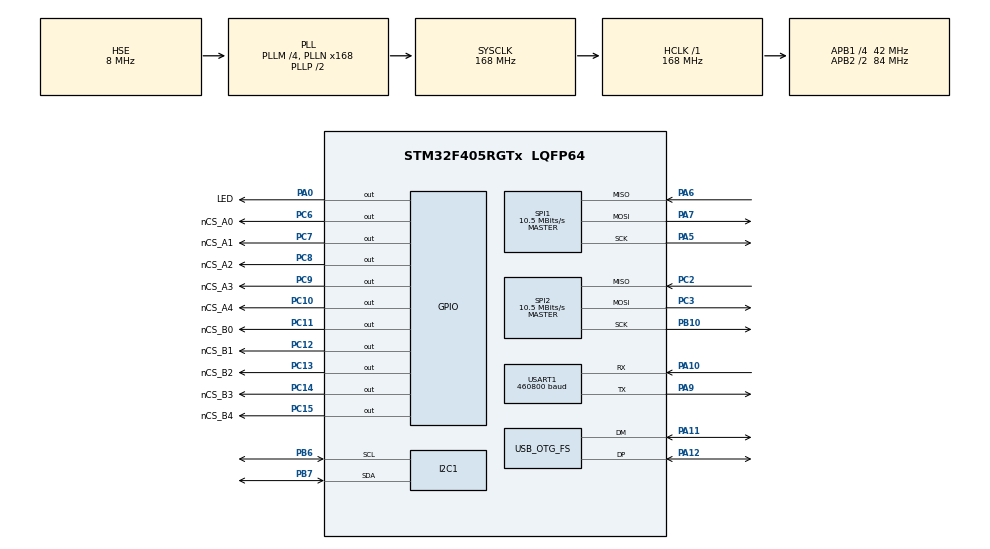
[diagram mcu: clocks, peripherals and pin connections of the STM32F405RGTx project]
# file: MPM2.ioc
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Dma.Request0=USART1_RX
Dma.USART1_RX.0.Direction=DMA_PERIPH_TO_MEMORY
Dma.USART1_RX.0.FIFOMode=DMA_FIFOMODE_DISABLE
Dma.USART1_RX.0.Instance=DMA2_Stream2
Dma.USART1_RX.0.MemDataAlignment=DMA_MDATAALIGN_BYTE
Dma.USART1_RX.0.MemInc=DMA_MINC_ENABLE
Dma.USART1_RX.0.Mode=DMA_NORMAL
Dma.USART1_RX.0.PeriphDataAlignment=DMA_PDATAALIGN_BYTE
Dma.USART1_RX.0.PeriphInc=DMA_PINC_DISABLE
Dma.USART1_RX.0.Priority=DMA_PRIORITY_LOW
FREERTOS.Tasks01=defaultTask,24,256,StartDefaultTask,Default,NULL,Dynamic,NULL,NULL;IdleTask,8,256,IdleTaskEntry,Default,NULL,Dynamic,NULL,NULL;MeasTask,8,256,MeasTaskEntry,Default,NULL,Dynamic,NULL,NULL;DisplayTask,8,256,DisplayTaskEntry,Default,NULL,Dynamic,NULL,NULL;SysTask,8,256,SysTaskEntry,Default,NULL,Dynamic,NULL,NULL
FREERTOS.configMINIMAL_STACK_SIZE=256
FREERTOS.configUSE_NEWLIB_REENTRANT=1
Mcu.Family=STM32F4
Mcu.Name=STM32F405RGTx
Mcu.Package=LQFP64
NVIC.DMA2_Stream2_IRQn=true\:5\:0\:false\:false\:true\:true\:false\:true\:true
NVIC.OTG_FS_IRQn=true\:5\:0\:false\:false\:true\:true\:false\:true\:true
NVIC.PriorityGroup=NVIC_PRIORITYGROUP_4
NVIC.TIM2_IRQn=true\:15\:0\:false\:false\:true\:false\:false\:true\:true
NVIC.TimeBase=TIM2_IRQn
NVIC.TimeBaseIP=TIM2
PA0-WKUP.GPIO_Label=LED
PA0-WKUP.GPIO_ModeDefaultOutputPP=GPIO_MODE_OUTPUT_OD
PA0-WKUP.GPIO_PuPd=GPIO_NOPULL
PA0-WKUP.PinState=GPIO_PIN_SET
PA0-WKUP.Signal=GPIO_Output
PA10.Mode=Asynchronous
PA10.Signal=USART1_RX
PA11.Mode=Device_Only
PA11.Signal=USB_OTG_FS_DM
PA12.Mode=Device_Only
PA12.Signal=USB_OTG_FS_DP
PA13.Signal=SYS_JTMS-SWDIO
PA14.Signal=SYS_JTCK-SWCLK
PA5.Mode=Full_Duplex_Master
PA5.Signal=SPI1_SCK
PA6.Mode=Full_Duplex_Master
PA6.Signal=SPI1_MISO
PA7.Mode=Full_Duplex_Master
PA7.Signal=SPI1_MOSI
PA9.Mode=Asynchronous
PA9.Signal=USART1_TX
PB10.Mode=Full_Duplex_Master
PB10.Signal=SPI2_SCK
PB6.Mode=I2C
PB6.Signal=I2C1_SCL
PB7.Mode=I2C
PB7.Signal=I2C1_SDA
PC10.GPIO_Label=nCS_A4
PC10.GPIO_PuPd=GPIO_PULLUP
PC10.GPIO_Speed=GPIO_SPEED_FREQ_HIGH
PC10.PinState=GPIO_PIN_SET
PC10.Signal=GPIO_Output
PC11.GPIO_Label=nCS_B0
PC11.GPIO_PuPd=GPIO_PULLUP
PC11.GPIO_Speed=GPIO_SPEED_FREQ_HIGH
PC11.PinState=GPIO_PIN_SET
PC11.Signal=GPIO_Output
PC12.GPIO_Label=nCS_B1
PC12.GPIO_PuPd=GPIO_PULLUP
PC12.GPIO_Speed=GPIO_SPEED_FREQ_HIGH
PC12.PinState=GPIO_PIN_SET
PC12.Signal=GPIO_Output
PC13-ANTI_TAMP.GPIO_Label=nCS_B2
PC13-ANTI_TAMP.GPIO_PuPd=GPIO_PULLUP
PC13-ANTI_TAMP.PinState=GPIO_PIN_SET
PC13-ANTI_TAMP.Signal=GPIO_Output
PC14-OSC32_IN.GPIO_Label=nCS_B3
PC14-OSC32_IN.GPIO_PuPd=GPIO_PULLUP
PC14-OSC32_IN.PinState=GPIO_PIN_SET
PC14-OSC32_IN.Signal=GPIO_Output
PC15-OSC32_OUT.GPIO_Label=nCS_B4
PC15-OSC32_OUT.GPIO_PuPd=GPIO_PULLUP
PC15-OSC32_OUT.PinState=GPIO_PIN_SET
PC15-OSC32_OUT.Signal=GPIO_Output
PC2.Mode=Full_Duplex_Master
PC2.Signal=SPI2_MISO
PC3.Mode=Full_Duplex_Master
PC3.Signal=SPI2_MOSI
PC6.GPIO_Label=nCS_A0
PC6.GPIO_PuPd=GPIO_PULLUP
PC6.GPIO_Speed=GPIO_SPEED_FREQ_HIGH
PC6.PinState=GPIO_PIN_SET
PC6.Signal=GPIO_Output
PC7.GPIO_Label=nCS_A1
PC7.GPIO_PuPd=GPIO_PULLUP
PC7.GPIO_Speed=GPIO_SPEED_FREQ_HIGH
PC7.PinState=GPIO_PIN_SET
PC7.Signal=GPIO_Output
PC8.GPIO_Label=nCS_A2
PC8.GPIO_PuPd=GPIO_PULLUP
PC8.GPIO_Speed=GPIO_SPEED_FREQ_HIGH
PC8.PinState=GPIO_PIN_SET
PC8.Signal=GPIO_Output
PC9.GPIO_Label=nCS_A3
PC9.GPIO_PuPd=GPIO_PULLUP
PC9.GPIO_Speed=GPIO_SPEED_FREQ_HIGH
PC9.PinState=GPIO_PIN_SET
PC9.Signal=GPIO_Output
PH0-OSC_IN.Mode=HSE-External-Oscillator
PH0-OSC_IN.Signal=RCC_OSC_IN
PH1-OSC_OUT.Mode=HSE-External-Oscillator
PH1-OSC_OUT.Signal=RCC_OSC_OUT
ProjectManager.HeapSize=0x200
ProjectManager.StackSize=0x400
ProjectManager.TargetToolchain=STM32CubeIDE
RCC.48MHZClocksFreq_Value=48000000
RCC.AHBFreq_Value=168000000
RCC.APB1CLKDivider=RCC_HCLK_DIV4
RCC.APB1Freq_Value=42000000
RCC.APB1TimFreq_Value=84000000
RCC.APB2CLKDivider=RCC_HCLK_DIV2
RCC.APB2Freq_Value=84000000
RCC.APB2TimFreq_Value=168000000
RCC.CortexFreq_Value=168000000
RCC.HCLKFreq_Value=168000000
RCC.HSE_VALUE=8000000
RCC.HSI_VALUE=16000000
RCC.LSE_VALUE=32768
RCC.PLLM=4
RCC.PLLN=168
RCC.PLLQ=7
RCC.PWR_Regulator_Voltage_Scale=PWR_REGULATOR_VOLTAGE_SCALE1
RCC.SYSCLKFreq_VALUE=168000000
RCC.SYSCLKSource=RCC_SYSCLKSOURCE_PLLCLK
RCC.VCOOutputFreq_Value=336000000
SPI1.BaudRatePrescaler=SPI_BAUDRATEPRESCALER_8
SPI1.CLKPhase=SPI_PHASE_1EDGE
SPI1.CLKPolarity=SPI_POLARITY_HIGH
SPI1.CalculateBaudRate=10.5 MBits/s
SPI1.DataSize=SPI_DATASIZE_8BIT
SPI1.Direction=SPI_DIRECTION_2LINES
SPI1.Mode=SPI_MODE_MASTER
SPI1.VirtualType=VM_MASTER
SPI2.BaudRatePrescaler=SPI_BAUDRATEPRESCALER_4
SPI2.CLKPolarity=SPI_POLARITY_HIGH
SPI2.CalculateBaudRate=10.5 MBits/s
SPI2.Direction=SPI_DIRECTION_2LINES
SPI2.Mode=SPI_MODE_MASTER
SPI2.VirtualType=VM_MASTER
USART1.BaudRate=460800
USART1.VirtualMode=VM_ASYNC
USB_DEVICE.CLASS_NAME_FS=CDC
USB_DEVICE.MANUFACTURER_STRING-CDC_FS=ioko.eu
USB_DEVICE.PRODUCT_STRING_CDC_FS=MPM Virtual ComPort
USB_DEVICE.VirtualMode-CDC_FS=Cdc
USB_DEVICE.VirtualModeFS=Cdc_FS
USB_OTG_FS.VirtualMode=Device_Only
VP_FREERTOS_VS_CMSIS_V2.Mode=CMSIS_V2
VP_SYS_VS_tim2.Mode=TIM2
VP_USB_DEVICE_VS_USB_DEVICE_CDC_FS.Mode=CDC_FS
board=custom

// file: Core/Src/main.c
/* USER CODE BEGIN Header */
/**
  ******************************************************************************
  * @file           : main.c
  * @brief          : Main program body
  ******************************************************************************
  * @attention
  *
  * Copyright (c) 2024 STMicroelectronics.
  * All rights reserved.
  *
  * This software is licensed under terms that can be found in the LICENSE file
  * in the root directory of this software component.
  * If no LICENSE file comes with this software, it is provided AS-IS.
  *
  ******************************************************************************
  */
/* USER CODE END Header */
#include "main.h"
#include "cmsis_os.h"
#include "usb_device.h"

I2C_HandleTypeDef hi2c1;

SPI_HandleTypeDef hspi1;
SPI_HandleTypeDef hspi2;

UART_HandleTypeDef huart1;
DMA_HandleTypeDef hdma_usart1_rx;

/* Definitions for defaultTask */
osThreadId_t defaultTaskHandle;
const osThreadAttr_t defaultTask_attributes = {
  .name = "defaultTask",
  .stack_size = 256 * 4,
  .priority = (osPriority_t) osPriorityNormal,
};
/* Definitions for IdleTask */
osThreadId_t IdleTaskHandle;
const osThreadAttr_t IdleTask_attributes = {
  .name = "IdleTask",
  .stack_size = 256 * 4,
  .priority = (osPriority_t) osPriorityLow,
};
/* Definitions for MeasTask */
osThreadId_t MeasTaskHandle;
const osThreadAttr_t MeasTask_attributes = {
  .name = "MeasTask",
  .stack_size = 256 * 4,
  .priority = (osPriority_t) osPriorityLow,
};
/* Definitions for DisplayTask */
osThreadId_t DisplayTaskHandle;
const osThreadAttr_t DisplayTask_attributes = {
  .name = "DisplayTask",
  .stack_size = 256 * 4,
  .priority = (osPriority_t) osPriorityLow,
};
/* Definitions for SysTask */
osThreadId_t SysTaskHandle;
const osThreadAttr_t SysTask_attributes = {
  .name = "SysTask",
  .stack_size = 256 * 4,
  .priority = (osPriority_t) osPriorityLow,
};

void SystemClock_Config(void);
static void MX_GPIO_Init(void);
static void MX_DMA_Init(void);
static void MX_SPI1_Init(void);
static void MX_SPI2_Init(void);
static void MX_USART1_UART_Init(void);
static void MX_I2C1_Init(void);
void StartDefaultTask(void *argument);
void IdleTaskEntry(void *argument);
void MeasTaskEntry(void *argument);
void DisplayTaskEntry(void *argument);
void SysTaskEntry(void *argument);

int main(void)
{

  /* MCU Configuration--------------------------------------------------------*/

  /* Reset of all peripherals, Initializes the Flash interface and the Systick. */
  HAL_Init();

  /* Configure the system clock */
  SystemClock_Config();

  /* Initialize all configured peripherals */
  MX_GPIO_Init();
  MX_DMA_Init();
  MX_SPI1_Init();
  MX_SPI2_Init();
  MX_USART1_UART_Init();
  MX_I2C1_Init();

  /* Init scheduler */
  osKernelInitialize();

  /* Create the thread(s) */
  /* creation of defaultTask */
  defaultTaskHandle = osThreadNew(StartDefaultTask, NULL, &defaultTask_attributes);

  /* creation of IdleTask */
  IdleTaskHandle = osThreadNew(IdleTaskEntry, NULL, &IdleTask_attributes);

  /* creation of MeasTask */
  MeasTaskHandle = osThreadNew(MeasTaskEntry, NULL, &MeasTask_attributes);

  /* creation of DisplayTask */
  DisplayTaskHandle = osThreadNew(DisplayTaskEntry, NULL, &DisplayTask_attributes);

  /* creation of SysTask */
  SysTaskHandle = osThreadNew(SysTaskEntry, NULL, &SysTask_attributes);

  /* Start scheduler */
  osKernelStart();

  /* We should never get here as control is now taken by the scheduler */

  /* Infinite loop */
  while (1)
  {

  }
}

void SystemClock_Config(void)
{
  RCC_OscInitTypeDef RCC_OscInitStruct = {0};
  RCC_ClkInitTypeDef RCC_ClkInitStruct = {0};

  /** Configure the main internal regulator output voltage
  */
  __HAL_RCC_PWR_CLK_ENABLE();
  __HAL_PWR_VOLTAGESCALING_CONFIG(PWR_REGULATOR_VOLTAGE_SCALE1);

  /** Initializes the RCC Oscillators according to the specified parameters
  * in the RCC_OscInitTypeDef structure.
  */
  RCC_OscInitStruct.OscillatorType = RCC_OSCILLATORTYPE_HSE;
  RCC_OscInitStruct.HSEState = RCC_HSE_ON;
  RCC_OscInitStruct.PLL.PLLState = RCC_PLL_ON;
  RCC_OscInitStruct.PLL.PLLSource = RCC_PLLSOURCE_HSE;
  RCC_OscInitStruct.PLL.PLLM = 4;
  RCC_OscInitStruct.PLL.PLLN = 168;
  RCC_OscInitStruct.PLL.PLLP = RCC_PLLP_DIV2;
  RCC_OscInitStruct.PLL.PLLQ = 7;
  if (HAL_RCC_OscConfig(&RCC_OscInitStruct) != HAL_OK)
  {
    Error_Handler();
  }

  /** Initializes the CPU, AHB and APB buses clocks
  */
  RCC_ClkInitStruct.ClockType = RCC_CLOCKTYPE_HCLK|RCC_CLOCKTYPE_SYSCLK
                              |RCC_CLOCKTYPE_PCLK1|RCC_CLOCKTYPE_PCLK2;
  RCC_ClkInitStruct.SYSCLKSource = RCC_SYSCLKSOURCE_PLLCLK;
  RCC_ClkInitStruct.AHBCLKDivider = RCC_SYSCLK_DIV1;
  RCC_ClkInitStruct.APB1CLKDivider = RCC_HCLK_DIV4;
  RCC_ClkInitStruct.APB2CLKDivider = RCC_HCLK_DIV2;

  if (HAL_RCC_ClockConfig(&RCC_ClkInitStruct, FLASH_LATENCY_5) != HAL_OK)
  {
    Error_Handler();
  }
}

static void MX_I2C1_Init(void)
{

  hi2c1.Instance = I2C1;
  hi2c1.Init.ClockSpeed = 100000;
  hi2c1.Init.DutyCycle = I2C_DUTYCYCLE_2;
  hi2c1.Init.OwnAddress1 = 0;
  hi2c1.Init.AddressingMode = I2C_ADDRESSINGMODE_7BIT;
  hi2c1.Init.DualAddressMode = I2C_DUALADDRESS_DISABLE;
  hi2c1.Init.OwnAddress2 = 0;
  hi2c1.Init.GeneralCallMode = I2C_GENERALCALL_DISABLE;
  hi2c1.Init.NoStretchMode = I2C_NOSTRETCH_DISABLE;
  if (HAL_I2C_Init(&hi2c1) != HAL_OK)
  {
    Error_Handler();
  }

}

static void MX_SPI1_Init(void)
{

  /* SPI1 parameter configuration*/
  hspi1.Instance = SPI1;
  hspi1.Init.Mode = SPI_MODE_MASTER;
  hspi1.Init.Direction = SPI_DIRECTION_2LINES;
  hspi1.Init.DataSize = SPI_DATASIZE_8BIT;
  hspi1.Init.CLKPolarity = SPI_POLARITY_HIGH;
  hspi1.Init.CLKPhase = SPI_PHASE_1EDGE;
  hspi1.Init.NSS = SPI_NSS_SOFT;
  hspi1.Init.BaudRatePrescaler = SPI_BAUDRATEPRESCALER_8;
  hspi1.Init.FirstBit = SPI_FIRSTBIT_MSB;
  hspi1.Init.TIMode = SPI_TIMODE_DISABLE;
  hspi1.Init.CRCCalculation = SPI_CRCCALCULATION_DISABLE;
  hspi1.Init.CRCPolynomial = 10;
  if (HAL_SPI_Init(&hspi1) != HAL_OK)
  {
    Error_Handler();
  }

}

static void MX_SPI2_Init(void)
{

  /* SPI2 parameter configuration*/
  hspi2.Instance = SPI2;
  hspi2.Init.Mode = SPI_MODE_MASTER;
  hspi2.Init.Direction = SPI_DIRECTION_2LINES;
  hspi2.Init.DataSize = SPI_DATASIZE_8BIT;
  hspi2.Init.CLKPolarity = SPI_POLARITY_HIGH;
  hspi2.Init.CLKPhase = SPI_PHASE_1EDGE;
  hspi2.Init.NSS = SPI_NSS_SOFT;
  hspi2.Init.BaudRatePrescaler = SPI_BAUDRATEPRESCALER_4;
  hspi2.Init.FirstBit = SPI_FIRSTBIT_MSB;
  hspi2.Init.TIMode = SPI_TIMODE_DISABLE;
  hspi2.Init.CRCCalculation = SPI_CRCCALCULATION_DISABLE;
  hspi2.Init.CRCPolynomial = 10;
  if (HAL_SPI_Init(&hspi2) != HAL_OK)
  {
    Error_Handler();
  }

}

static void MX_USART1_UART_Init(void)
{

  huart1.Instance = USART1;
  huart1.Init.BaudRate = 460800;
  huart1.Init.WordLength = UART_WORDLENGTH_8B;
  huart1.Init.StopBits = UART_STOPBITS_1;
  huart1.Init.Parity = UART_PARITY_NONE;
  huart1.Init.Mode = UART_MODE_TX_RX;
  huart1.Init.HwFlowCtl = UART_HWCONTROL_NONE;
  huart1.Init.OverSampling = UART_OVERSAMPLING_16;
  if (HAL_UART_Init(&huart1) != HAL_OK)
  {
    Error_Handler();
  }

}

static void MX_DMA_Init(void)
{

  /* DMA controller clock enable */
  __HAL_RCC_DMA2_CLK_ENABLE();

  /* DMA interrupt init */
  /* DMA2_Stream2_IRQn interrupt configuration */
  HAL_NVIC_SetPriority(DMA2_Stream2_IRQn, 5, 0);
  HAL_NVIC_EnableIRQ(DMA2_Stream2_IRQn);

}

static void MX_GPIO_Init(void)
{
  GPIO_InitTypeDef GPIO_InitStruct = {0};

  /* GPIO Ports Clock Enable */
  __HAL_RCC_GPIOC_CLK_ENABLE();
  __HAL_RCC_GPIOH_CLK_ENABLE();
  __HAL_RCC_GPIOA_CLK_ENABLE();
  __HAL_RCC_GPIOB_CLK_ENABLE();

  /*Configure GPIO pin Output Level */
  HAL_GPIO_WritePin(GPIOC, nCS_B2_Pin|nCS_B3_Pin|nCS_B4_Pin|nCS_A0_Pin
                          |nCS_A1_Pin|nCS_A2_Pin|nCS_A3_Pin|nCS_A4_Pin
                          |nCS_B0_Pin|nCS_B1_Pin, GPIO_PIN_SET);

  /*Configure GPIO pin Output Level */
  HAL_GPIO_WritePin(LED_GPIO_Port, LED_Pin, GPIO_PIN_SET);

  /*Configure GPIO pins : nCS_B2_Pin nCS_B3_Pin nCS_B4_Pin */
  GPIO_InitStruct.Pin = nCS_B2_Pin|nCS_B3_Pin|nCS_B4_Pin;
  GPIO_InitStruct.Mode = GPIO_MODE_OUTPUT_PP;
  GPIO_InitStruct.Pull = GPIO_PULLUP;
  GPIO_InitStruct.Speed = GPIO_SPEED_FREQ_LOW;
  HAL_GPIO_Init(GPIOC, &GPIO_InitStruct);

  /*Configure GPIO pin : LED_Pin */
  GPIO_InitStruct.Pin = LED_Pin;
  GPIO_InitStruct.Mode = GPIO_MODE_OUTPUT_OD;
  GPIO_InitStruct.Pull = GPIO_NOPULL;
  GPIO_InitStruct.Speed = GPIO_SPEED_FREQ_LOW;
  HAL_GPIO_Init(LED_GPIO_Port, &GPIO_InitStruct);

  /*Configure GPIO pins : nCS_A0_Pin nCS_A1_Pin nCS_A2_Pin nCS_A3_Pin
                           nCS_A4_Pin nCS_B0_Pin nCS_B1_Pin */
  GPIO_InitStruct.Pin = nCS_A0_Pin|nCS_A1_Pin|nCS_A2_Pin|nCS_A3_Pin
                          |nCS_A4_Pin|nCS_B0_Pin|nCS_B1_Pin;
  GPIO_InitStruct.Mode = GPIO_MODE_OUTPUT_PP;
  GPIO_InitStruct.Pull = GPIO_PULLUP;
  GPIO_InitStruct.Speed = GPIO_SPEED_FREQ_HIGH;
  HAL_GPIO_Init(GPIOC, &GPIO_InitStruct);

}

void StartDefaultTask(void *argument)
{
  /* init code for USB_DEVICE */
  MX_USB_DEVICE_Init();
  /* USER CODE BEGIN 5 */
  /* Infinite loop */
  for(;;)
  {
    osDelay(1000);
  }
  /* USER CODE END 5 */
}

void IdleTaskEntry(void *argument)
{
  /* USER CODE BEGIN IdleTaskEntry */
  /* Infinite loop */
  for(;;)
  {
    osDelay(500);
    HAL_GPIO_TogglePin(LED_GPIO_Port, LED_Pin);
  }
  /* USER CODE END IdleTaskEntry */
}

void MeasTaskEntry(void *argument)
{
  /* USER CODE BEGIN MeasTaskEntry */

  InitAllIna(hspi1, hspi2);

  /* Infinite loop */
  for(;;)
  {
    osDelay(100);
    CDC_Transmit_FS("Meas task running\n\r", sizeof("Meas task running\n\r"));
    ReadAll_A(hspi1);
    ReadAll_B(hspi2);

  }
  /* USER CODE END MeasTaskEntry */
}

void DisplayTaskEntry(void *argument)
{
  /* USER CODE BEGIN DisplayTaskEntry */
  /* Infinite loop */
  for(;;)
  {
    osDelay(100);
  }
  /* USER CODE END DisplayTaskEntry */
}

void SysTaskEntry(void *argument)
{
  /* USER CODE BEGIN SysTaskEntry */
  /* Infinite loop */
  for(;;)
  {
    osDelay(1000);
  }
  /* USER CODE END SysTaskEntry */
}

void HAL_TIM_PeriodElapsedCallback(TIM_HandleTypeDef *htim)
{
  if (htim->Instance == TIM2) {
    HAL_IncTick();
  }
}

void Error_Handler(void)
{
  __disable_irq();
  while (1)
  {
  }
}
